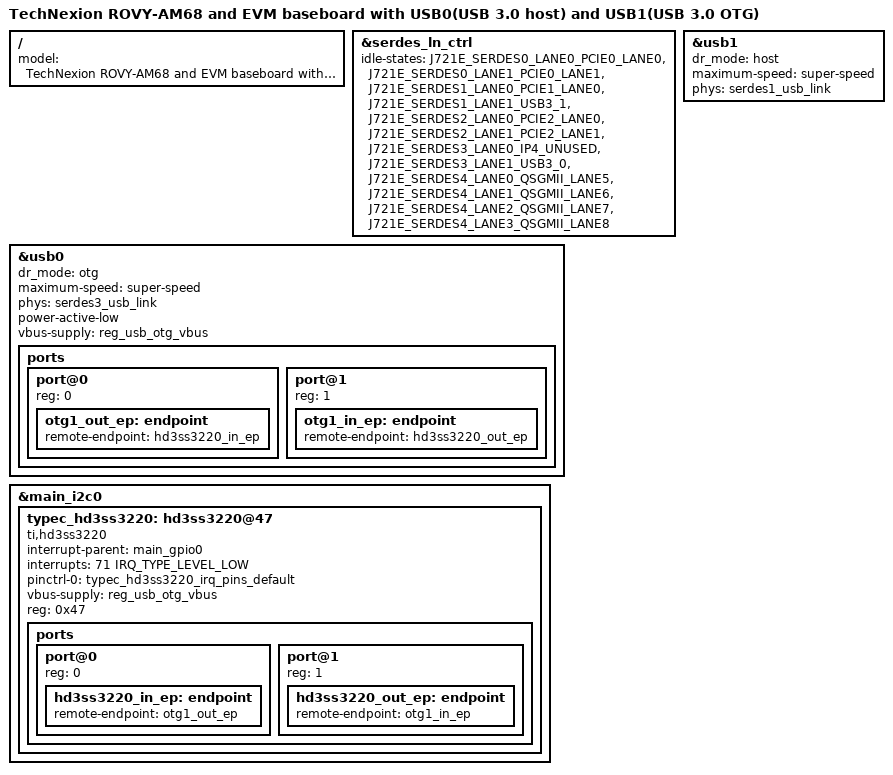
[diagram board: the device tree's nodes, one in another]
// SPDX-License-Identifier: GPL-2.0
/*
 * Copyright 2022 Technexion Ltd.
 *
 * Author: Richard Hu <richard.hu@technexion.com>
 *
 */

/dts-v1/;
/plugin/;

#include <dt-bindings/gpio/gpio.h>
#include <dt-bindings/interrupt-controller/irq.h>
#include <dt-bindings/pinctrl/k3.h>
#include <dt-bindings/mux/ti-serdes.h>
#include <dt-bindings/phy/phy.h>

/ {
	fragment@101 {
		target-path = "/";

		__overlay__ {
			model = "TechNexion ROVY-AM68 and EVM baseboard with USB0(USB 3.0 host) and USB1(USB 3.0 OTG)";
		};
	};
};

&serdes_ln_ctrl {
	idle-states = <J721E_SERDES0_LANE0_PCIE0_LANE0>, <J721E_SERDES0_LANE1_PCIE0_LANE1>,
		      <J721E_SERDES1_LANE0_PCIE1_LANE0>, <J721E_SERDES1_LANE1_USB3_1>,
		      <J721E_SERDES2_LANE0_PCIE2_LANE0>, <J721E_SERDES2_LANE1_PCIE2_LANE1>,
		      <J721E_SERDES3_LANE0_IP4_UNUSED>, <J721E_SERDES3_LANE1_USB3_0>,
		      <J721E_SERDES4_LANE0_QSGMII_LANE5>, <J721E_SERDES4_LANE1_QSGMII_LANE6>,
		      <J721E_SERDES4_LANE2_QSGMII_LANE7>, <J721E_SERDES4_LANE3_QSGMII_LANE8>;
};


&usb0 {
	dr_mode = "otg";
	maximum-speed = "super-speed";
	phys = <&serdes3_usb_link>;
	phy-names = "cdns3,usb3-phy";
	power-active-low;
	vbus-supply = <&reg_usb_otg_vbus>;

	ports {
		#address-cells = <1>;
		#size-cells = <0>;

		port@0 {
			reg = <0>;
			otg1_out_ep: endpoint {
				remote-endpoint = <&hd3ss3220_in_ep>;
			};
		};

		port@1 {
			reg = <1>;
			otg1_in_ep: endpoint {
				remote-endpoint = <&hd3ss3220_out_ep>;
			};
		};
	};
};

&main_i2c0 { /* I2C_A */
	#address-cells = <1>;
	#size-cells = <0>;

	typec_hd3ss3220: hd3ss3220@47 {
		compatible = "ti,hd3ss3220";
		interrupt-parent = <&main_gpio0>;
		interrupts = <71 IRQ_TYPE_LEVEL_LOW>;
		pinctrl-names = "default";
		pinctrl-0 = <&typec_hd3ss3220_irq_pins_default>;
		vbus-supply = <&reg_usb_otg_vbus>;
		reg = <0x47>;

		ports {
			#address-cells = <1>;
			#size-cells = <0>;

			port@0 {
				reg = <0>;
				hd3ss3220_in_ep: endpoint {
					remote-endpoint = <&otg1_out_ep>;
				};
			};

			port@1 {
				reg = <1>;
				hd3ss3220_out_ep: endpoint {
					remote-endpoint = <&otg1_in_ep>;
				};
			};
		};
	};
};

&usb1 {
	dr_mode = "host";
	maximum-speed = "super-speed";
	phys = <&serdes1_usb_link>;
	phy-names = "cdns3,usb3-phy";
};
